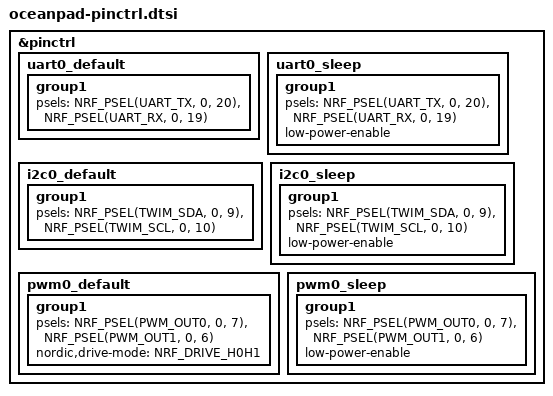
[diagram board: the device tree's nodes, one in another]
&pinctrl {
    uart0_default: uart0_default {
        group1 {
            psels = <NRF_PSEL(UART_TX, 0, 20)>,
                    <NRF_PSEL(UART_RX, 0, 19)>;
        };
    };

    uart0_sleep: uart0_sleep {
        group1 {
            psels = <NRF_PSEL(UART_TX, 0, 20)>,
                    <NRF_PSEL(UART_RX, 0, 19)>;
            low-power-enable;
        };
    };

    i2c0_default: i2c0_default {
        group1 {
            psels = <NRF_PSEL(TWIM_SDA, 0, 9)>,
                    <NRF_PSEL(TWIM_SCL, 0, 10)>;
        };
    };

    i2c0_sleep: i2c0_sleep {
        group1 {
            psels = <NRF_PSEL(TWIM_SDA, 0, 9)>,
                    <NRF_PSEL(TWIM_SCL, 0, 10)>;
            low-power-enable;
        };
    };

    pwm0_default: pwm0_default {
        group1 {
            psels = <NRF_PSEL(PWM_OUT0, 0, 7)>,  /* Heavy Motor */
                    <NRF_PSEL(PWM_OUT1, 0, 6)>;  /* Small Motor */
            nordic,drive-mode = <NRF_DRIVE_H0H1>;
        };
    };

    pwm0_sleep: pwm0_sleep {
        group1 {
            psels = <NRF_PSEL(PWM_OUT0, 0, 7)>,
                    <NRF_PSEL(PWM_OUT1, 0, 6)>;
            low-power-enable;
        };
    };
};
